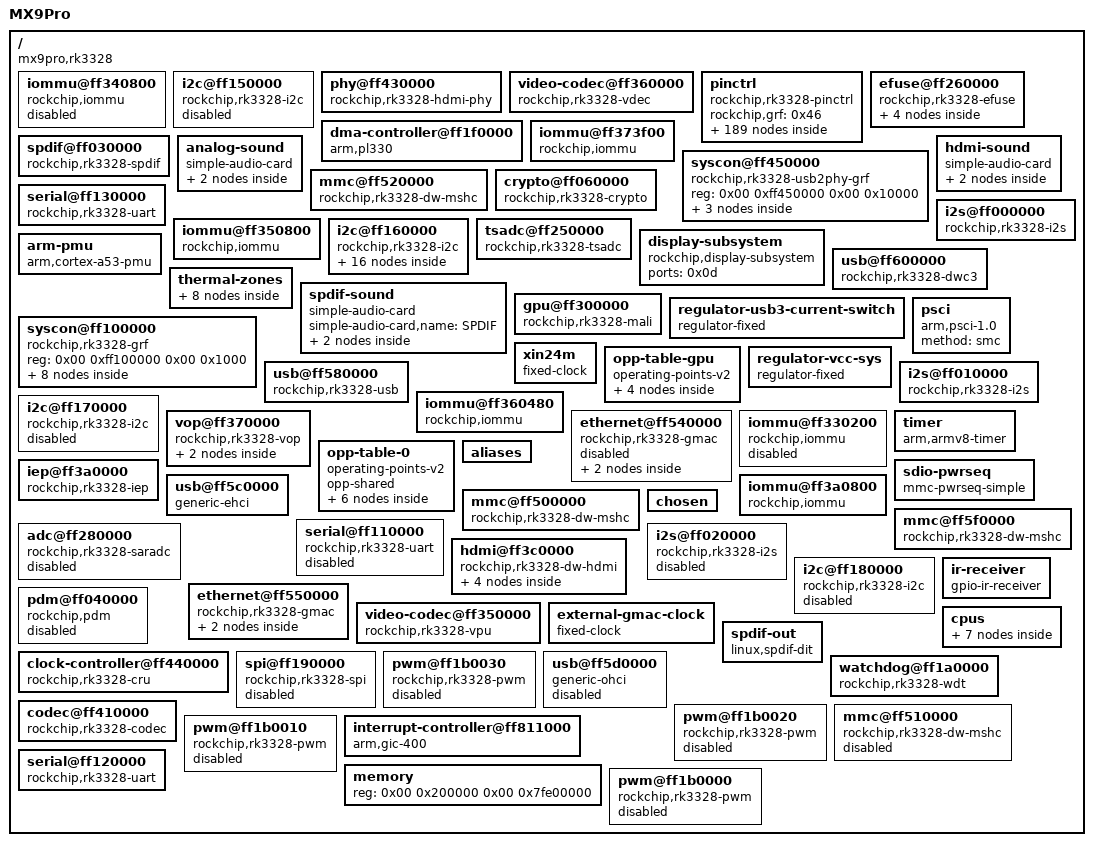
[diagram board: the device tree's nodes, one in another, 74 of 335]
/dts-v1/;

/ {
	#address-cells = <0x02>;
	model = "MX9Pro";
	serial-number = "0ee56abe064fdcdd";
	#size-cells = <0x02>;
	interrupt-parent = <0x01>;
	compatible = "mx9pro,rk3328\0rockchip,rk3328";

	iommu@ff340800 {
		clock-names = "aclk\0iface";
		interrupts = <0x00 0x62 0x04>;
		clocks = <0x02 0x8f 0x02 0x146>;
		#iommu-cells = <0x00>;
		compatible = "rockchip,iommu";
		status = "disabled";
		reg = <0x00 0xff340800 0x00 0x40>;
		phandle = <0x8f>;
	};

	i2c@ff150000 {
		pinctrl-names = "default";
		#address-cells = <0x01>;
		pinctrl-0 = <0x26>;
		clock-names = "i2c\0pclk";
		interrupts = <0x00 0x24 0x04>;
		clocks = <0x02 0x37 0x02 0xcd>;
		#size-cells = <0x00>;
		compatible = "rockchip,rk3328-i2c\0rockchip,rk3399-i2c";
		status = "disabled";
		reg = <0x00 0xff150000 0x00 0x1000>;
		phandle = <0x7a>;
	};

	phy@ff430000 {
		nvmem-cells = <0x4a>;
		clock-output-names = "hdmi_phy";
		clock-names = "sysclk\0refoclk\0refpclk";
		interrupts = <0x00 0x53 0x04>;
		clocks = <0x02 0xe4 0x49 0x02 0x79>;
		#clock-cells = <0x00>;
		#phy-cells = <0x00>;
		compatible = "rockchip,rk3328-hdmi-phy";
		status = "okay";
		nvmem-cell-names = "cpu-version";
		reg = <0x00 0xff430000 0x00 0x10000>;
		phandle = <0x42>;
	};

	video-codec@ff360000 {
		power-domains = <0x3b 0x05>;
		iommus = <0x3e>;
		clock-names = "axi\0ahb\0cabac\0core";
		assigned-clocks = <0x02 0x8b 0x02 0x41 0x02 0x42>;
		assigned-clock-rates = <0x1dcd6500 0x1dcd6500 0x11e1a300>;
		resets = <0x02 0xa6 0x02 0xa4 0x02 0xa8 0x02 0xa9 0x02 0xa5 0x02 0xa7>;
		interrupts = <0x00 0x07 0x04>;
		clocks = <0x02 0x8b 0x02 0x142 0x02 0x41 0x02 0x42>;
		compatible = "rockchip,rk3328-vdec\0rockchip,rk3399-vdec";
		reg = <0x00 0xff360000 0x00 0x480>;
		phandle = <0x91>;
		reset-names = "video_h\0video_a\0video_core\0video_cabac\0niu_a\0niu_h";
	};

	pinctrl {
		#address-cells = <0x02>;
		#size-cells = <0x02>;
		compatible = "rockchip,rk3328-pinctrl";
		ranges;
		rockchip,grf = <0x46>;
		phandle = <0xa2>;

		i2c3 {

			i2c3-xfer {
				rockchip,pins = <0x00 0x05 0x02 0x61 0x00 0x06 0x02 0x61>;
				phandle = <0x2c>;
			};

			i2c3-pins {
				rockchip,pins = <0x00 0x05 0x00 0x61 0x00 0x06 0x00 0x61>;
				phandle = <0xa8>;
			};
		};

		pcfg-pull-none-12ma {
			drive-strength = <0x0c>;
			bias-disable;
			phandle = <0x68>;
		};

		i2s1 {

			i2s1-lrcktx {
				rockchip,pins = <0x02 0x11 0x01 0x61>;
				phandle = <0xbb>;
			};

			i2s1-lrckrx {
				rockchip,pins = <0x02 0x10 0x01 0x61>;
				phandle = <0xba>;
			};

			i2s1-sleep {
				rockchip,pins = <0x02 0x0f 0x00 0x62 0x02 0x10 0x00 0x62 0x02 0x11 0x00 0x62 0x02 0x12 0x00 0x62 0x02 0x13 0x00 0x62 0x02 0x14 0x00 0x62 0x02 0x15 0x00 0x62 0x02 0x16 0x00 0x62 0x02 0x17 0x00 0x62>;
				phandle = <0xc1>;
			};

			i2s1-mclk {
				rockchip,pins = <0x02 0x0f 0x01 0x61>;
				phandle = <0xb8>;
			};

			i2s1-sdio3 {
				rockchip,pins = <0x02 0x16 0x01 0x61>;
				phandle = <0xc0>;
			};

			i2s1-sdio1 {
				rockchip,pins = <0x02 0x14 0x01 0x61>;
				phandle = <0xbe>;
			};

			i2s1-sdo {
				rockchip,pins = <0x02 0x17 0x01 0x61>;
				phandle = <0xbd>;
			};

			i2s1-sdi {
				rockchip,pins = <0x02 0x13 0x01 0x61>;
				phandle = <0xbc>;
			};

			i2s1-sdio2 {
				rockchip,pins = <0x02 0x15 0x01 0x61>;
				phandle = <0xbf>;
			};

			i2s1-sclk {
				rockchip,pins = <0x02 0x12 0x01 0x61>;
				phandle = <0xb9>;
			};
		};

		i2c1 {

			i2c1-xfer {
				rockchip,pins = <0x02 0x04 0x02 0x61 0x02 0x05 0x02 0x61>;
				phandle = <0x27>;
			};
		};

		usb3 {

			usb30-host-drv {
				rockchip,pins = <0x00 0x00 0x00 0x61>;
				phandle = <0x6f>;
			};
		};

		gpio@ff230000 {
			gpio-controller;
			interrupts = <0x00 0x35 0x04>;
			clocks = <0x02 0xca>;
			compatible = "rockchip,gpio-bank";
			#interrupt-cells = <0x02>;
			reg = <0x00 0xff230000 0x00 0x100>;
			phandle = <0x28>;
			#gpio-cells = <0x02>;
			interrupt-controller;
		};

		cif-1 {

			dvp-d2d9-m1 {
				rockchip,pins = <0x03 0x04 0x02 0x61 0x03 0x05 0x02 0x61 0x03 0x06 0x02 0x61 0x03 0x07 0x02 0x61 0x03 0x08 0x02 0x61 0x02 0x10 0x04 0x61 0x02 0x11 0x04 0x61 0x02 0x12 0x04 0x61 0x03 0x01 0x02 0x61 0x03 0x00 0x02 0x61 0x02 0x0f 0x04 0x61 0x03 0x02 0x02 0x61>;
				phandle = <0xf3>;
			};
		};

		spdif-2 {

			spdifm2-tx {
				rockchip,pins = <0x00 0x02 0x02 0x61>;
				phandle = <0x11>;
			};
		};

		pcfg-pull-down-4ma {
			drive-strength = <0x04>;
			bias-pull-down;
			phandle = <0xa6>;
		};

		wifi {

			host-wake-bt {
				rockchip,pins = <0x02 0x0f 0x00 0x6d>;
				phandle = <0x5e>;
			};

			chip-en {
				rockchip,pins = <0x02 0x13 0x00 0x6c>;
				phandle = <0x5d>;
			};

			bt-wake-host {
				rockchip,pins = <0x02 0x10 0x00 0x63>;
				phandle = <0x5c>;
			};

			wl-wake-host {
				rockchip,pins = <0x03 0x01 0x00 0x63>;
				phandle = <0x60>;
			};

			wifi_enable_h {
				rockchip,pins = <0x03 0x08 0x00 0x61>;
				phandle = <0xf8>;
			};

			wl-dis {
				rockchip,pins = <0x03 0x08 0x00 0x6c>;
				phandle = <0x5f>;
			};

			bt-dis {
				rockchip,pins = <0x02 0x15 0x00 0x6c>;
				phandle = <0x5b>;
			};
		};

		spi0-2 {

			spi0m2-tx {
				rockchip,pins = <0x03 0x01 0x04 0x63>;
				phandle = <0x2e>;
			};

			spi0m2-clk {
				rockchip,pins = <0x03 0x00 0x04 0x63>;
				phandle = <0x2d>;
			};

			spi0m2-rx {
				rockchip,pins = <0x03 0x02 0x04 0x63>;
				phandle = <0x2f>;
			};

			spi0m2-cs0 {
				rockchip,pins = <0x03 0x08 0x03 0x63>;
				phandle = <0x30>;
			};
		};

		pcfg-pull-none-2ma {
			drive-strength = <0x02>;
			bias-disable;
			phandle = <0x6a>;
		};

		sdmmc0-0 {

			sdmmc0m0-pwren {
				rockchip,pins = <0x02 0x07 0x01 0x64>;
				phandle = <0xd2>;
			};

			sdmmc0m0-pin {
				rockchip,pins = <0x02 0x07 0x00 0x64>;
				phandle = <0xd3>;
			};
		};

		spdif-0 {

			spdifm0-tx {
				rockchip,pins = <0x00 0x1b 0x01 0x61>;
				phandle = <0xd0>;
			};
		};

		tsadc_pin {

			tsadc-pin {
				rockchip,pins = <0x02 0x0d 0x00 0x61>;
				phandle = <0xf1>;
			};

			tsadc-int {
				rockchip,pins = <0x02 0x0d 0x02 0x61>;
				phandle = <0xf0>;
			};
		};

		pcfg-pull-down {
			bias-pull-down;
			phandle = <0x6b>;
		};

		gmac-1 {

			rgmiim1-pins {
				rockchip,pins = <0x01 0x0c 0x02 0x65 0x01 0x0d 0x02 0x67 0x01 0x13 0x02 0x67 0x01 0x19 0x02 0x65 0x01 0x15 0x02 0x67 0x01 0x16 0x02 0x67 0x01 0x17 0x02 0x67 0x01 0x0a 0x02 0x67 0x01 0x0b 0x02 0x67 0x01 0x08 0x02 0x65 0x01 0x09 0x02 0x65 0x01 0x0e 0x02 0x67 0x01 0x0f 0x02 0x67 0x01 0x10 0x02 0x65 0x01 0x11 0x02 0x65 0x00 0x08 0x01 0x65 0x00 0x0c 0x01 0x65 0x00 0x18 0x01 0x67 0x00 0x10 0x01 0x65 0x00 0x11 0x01 0x65 0x00 0x17 0x01 0x65 0x00 0x16 0x01 0x65>;
				phandle = <0x55>;
			};

			rmiim1-pins {
				rockchip,pins = <0x01 0x13 0x02 0x6a 0x01 0x19 0x02 0x68 0x01 0x15 0x02 0x6a 0x01 0x18 0x02 0x6a 0x01 0x16 0x02 0x6a 0x01 0x17 0x02 0x6a 0x01 0x0a 0x02 0x6a 0x01 0x0b 0x02 0x6a 0x01 0x08 0x02 0x68 0x01 0x09 0x02 0x68 0x00 0x0b 0x01 0x61 0x00 0x0c 0x01 0x61 0x00 0x18 0x01 0x61 0x00 0x13 0x01 0x61 0x00 0x10 0x01 0x61 0x00 0x11 0x01 0x61>;
				phandle = <0xec>;
			};
		};

		spi0-0 {

			spi0m0-cs0 {
				rockchip,pins = <0x02 0x0b 0x01 0x63>;
				phandle = <0xaf>;
			};

			spi0m0-cs1 {
				rockchip,pins = <0x02 0x0c 0x01 0x63>;
				phandle = <0xb2>;
			};

			spi0m0-clk {
				rockchip,pins = <0x02 0x08 0x01 0x63>;
				phandle = <0xae>;
			};

			spi0m0-tx {
				rockchip,pins = <0x02 0x09 0x01 0x63>;
				phandle = <0xb0>;
			};

			spi0m0-rx {
				rockchip,pins = <0x02 0x0a 0x01 0x63>;
				phandle = <0xb1>;
			};
		};

		i2s2-0 {

			i2s2m0-mclk {
				rockchip,pins = <0x01 0x15 0x01 0x61>;
				phandle = <0xc2>;
			};

			i2s2m0-lrcktx {
				rockchip,pins = <0x01 0x17 0x01 0x61>;
				phandle = <0xc5>;
			};

			i2s2m0-sdi {
				rockchip,pins = <0x01 0x18 0x01 0x61>;
				phandle = <0xc6>;
			};

			i2s2m0-lrckrx {
				rockchip,pins = <0x01 0x1a 0x01 0x61>;
				phandle = <0xc4>;
			};

			i2s2m0-sleep {
				rockchip,pins = <0x01 0x15 0x00 0x62 0x01 0x16 0x00 0x62 0x01 0x1a 0x00 0x62 0x01 0x17 0x00 0x62 0x01 0x18 0x00 0x62 0x01 0x19 0x00 0x62>;
				phandle = <0xc8>;
			};

			i2s2m0-sclk {
				rockchip,pins = <0x01 0x16 0x01 0x61>;
				phandle = <0xc3>;
			};

			i2s2m0-sdo {
				rockchip,pins = <0x01 0x19 0x01 0x61>;
				phandle = <0xc7>;
			};
		};

		hdmi_i2c {

			hdmii2c-xfer {
				rockchip,pins = <0x00 0x05 0x01 0x61 0x00 0x06 0x01 0x61>;
				phandle = <0x44>;
			};
		};

		gpio@ff240000 {
			gpio-controller;
			interrupts = <0x00 0x36 0x04>;
			clocks = <0x02 0xcb>;
			compatible = "rockchip,gpio-bank";
			#interrupt-cells = <0x02>;
			reg = <0x00 0xff240000 0x00 0x100>;
			phandle = <0xa4>;
			#gpio-cells = <0x02>;
			interrupt-controller;
		};

		sdmmc1 {

			sdmmc1-cmd {
				rockchip,pins = <0x01 0x0d 0x01 0x66>;
				phandle = <0xe1>;
			};

			sdmmc1-pins {
				rockchip,pins = <0x01 0x0c 0x00 0x64 0x01 0x0d 0x00 0x64 0x01 0x0e 0x00 0x64 0x01 0x0f 0x00 0x64 0x01 0x10 0x00 0x64 0x01 0x11 0x00 0x64 0x01 0x12 0x00 0x64 0x01 0x13 0x00 0x64 0x01 0x14 0x00 0x64>;
				phandle = <0xe7>;
			};

			sdmmc1-bus1 {
				rockchip,pins = <0x01 0x0e 0x01 0x66>;
				phandle = <0xe5>;
			};

			sdmmc1-clk {
				rockchip,pins = <0x01 0x0c 0x01 0x65>;
				phandle = <0xe0>;
			};

			sdmmc1-bus4 {
				rockchip,pins = <0x01 0x0e 0x01 0x66 0x01 0x0f 0x01 0x66 0x01 0x10 0x01 0x66 0x01 0x11 0x01 0x66>;
				phandle = <0xe6>;
			};

			sdmmc1-pwren {
				rockchip,pins = <0x01 0x12 0x01 0x66>;
				phandle = <0xe2>;
			};

			sdmmc1-dectn {
				rockchip,pins = <0x01 0x13 0x01 0x66>;
				phandle = <0xe4>;
			};

			sdmmc1-wrprt {
				rockchip,pins = <0x01 0x14 0x01 0x66>;
				phandle = <0xe3>;
			};
		};

		pcfg-pull-none-8ma {
			drive-strength = <0x08>;
			bias-disable;
			phandle = <0x65>;
		};

		pwm1 {

			pwm1-pin {
				rockchip,pins = <0x02 0x05 0x01 0x61>;
				phandle = <0x32>;
			};
		};

		tsadc {

			otp-pin {
				rockchip,pins = <0x02 0x0d 0x00 0x61>;
				phandle = <0x38>;
			};

			otp-out {
				rockchip,pins = <0x02 0x0d 0x01 0x61>;
				phandle = <0x39>;
			};
		};

		pwmir {

			pwmir-pin {
				rockchip,pins = <0x02 0x02 0x01 0x61>;
				phandle = <0x34>;
			};
		};

		uart2-1 {

			uart2m1-xfer {
				rockchip,pins = <0x02 0x00 0x01 0x61 0x02 0x01 0x01 0x63>;
				phandle = <0x25>;
			};
		};

		uart0 {

			uart0-rts-pin {
				rockchip,pins = <0x01 0x0a 0x00 0x61>;
				phandle = <0xab>;
			};

			uart0-cts {
				rockchip,pins = <0x01 0x0b 0x01 0x61>;
				phandle = <0x20>;
			};

			uart0-rts {
				rockchip,pins = <0x01 0x0a 0x01 0x61>;
				phandle = <0x21>;
			};

			uart0-xfer {
				rockchip,pins = <0x01 0x09 0x01 0x61 0x01 0x08 0x01 0x63>;
				phandle = <0x1f>;
			};
		};

		emmc {

			emmc-clk {
				rockchip,pins = <0x03 0x15 0x02 0x68>;
				phandle = <0x50>;
			};

			emmc-bus1 {
				rockchip,pins = <0x00 0x07 0x02 0x69>;
				phandle = <0xea>;
			};

			emmc-bus8 {
				rockchip,pins = <0x00 0x07 0x02 0x69 0x02 0x1c 0x02 0x69 0x02 0x1d 0x02 0x69 0x02 0x1e 0x02 0x69 0x02 0x1f 0x02 0x69 0x03 0x10 0x02 0x69 0x03 0x11 0x02 0x69 0x03 0x12 0x02 0x69>;
				phandle = <0x52>;
			};

			emmc-bus4 {
				rockchip,pins = <0x00 0x07 0x02 0x69 0x02 0x1c 0x02 0x69 0x02 0x1d 0x02 0x69 0x02 0x1e 0x02 0x69>;
				phandle = <0xeb>;
			};

			emmc-pwren {
				rockchip,pins = <0x03 0x16 0x02 0x61>;
				phandle = <0xe8>;
			};

			emmc-cmd {
				rockchip,pins = <0x03 0x13 0x02 0x69>;
				phandle = <0x51>;
			};

			emmc-rstnout {
				rockchip,pins = <0x03 0x14 0x02 0x61>;
				phandle = <0xe9>;
			};
		};

		pcfg-output-high {
			output-high;
			phandle = <0x6d>;
		};

		pcfg-pull-up {
			phandle = <0x63>;
			bias-pull-up;
		};

		sdmmc0ext {

			sdmmc0ext-clk {
				rockchip,pins = <0x03 0x02 0x03 0x67>;
				phandle = <0xd9>;
			};

			sdmmc0ext-bus4 {
				rockchip,pins = <0x03 0x04 0x03 0x64 0x03 0x05 0x03 0x64 0x03 0x06 0x03 0x64 0x03 0x07 0x03 0x64>;
				phandle = <0xde>;
			};

			sdmmc0ext-wrprt {
				rockchip,pins = <0x03 0x03 0x03 0x64>;
				phandle = <0xdb>;
			};

			sdmmc0ext-pins {
				rockchip,pins = <0x03 0x00 0x00 0x64 0x03 0x01 0x00 0x64 0x03 0x02 0x00 0x64 0x03 0x03 0x00 0x64 0x03 0x04 0x00 0x64 0x03 0x05 0x00 0x64 0x03 0x06 0x00 0x64 0x03 0x07 0x00 0x64>;
				phandle = <0xdf>;
			};

			sdmmc0ext-bus1 {
				rockchip,pins = <0x03 0x04 0x03 0x64>;
				phandle = <0xdd>;
			};

			sdmmc0ext-cmd {
				rockchip,pins = <0x03 0x00 0x03 0x64>;
				phandle = <0xda>;
			};

			sdmmc0ext-dectn {
				rockchip,pins = <0x03 0x01 0x03 0x64>;
				phandle = <0xdc>;
			};
		};

		pcfg-input {
			phandle = <0xa7>;
			input-enable;
		};

		pcfg-pull-up-2ma {
			drive-strength = <0x02>;
			phandle = <0xa5>;
			bias-pull-up;
		};

		i2c2 {

			i2c2-xfer {
				rockchip,pins = <0x02 0x0d 0x01 0x61 0x02 0x0e 0x01 0x61>;
				phandle = <0x2b>;
			};
		};

		pmic {

			pmic-int-l {
				rockchip,pins = <0x02 0x06 0x00 0x63>;
				phandle = <0x29>;
			};
		};

		pcfg-pull-none {
			bias-disable;
			phandle = <0x61>;
		};

		pcfg-pull-none-4ma {
			drive-strength = <0x04>;
			bias-disable;
			phandle = <0x67>;
		};

		gpio@ff210000 {
			gpio-controller;
			interrupts = <0x00 0x33 0x04>;
			clocks = <0x02 0xc8>;
			compatible = "rockchip,gpio-bank";
			#interrupt-cells = <0x02>;
			reg = <0x00 0xff210000 0x00 0x100>;
			phandle = <0x6e>;
			#gpio-cells = <0x02>;
			interrupt-controller;
		};

		pdm-0 {

			pdmm0-sdi3 {
				rockchip,pins = <0x02 0x16 0x02 0x61>;
				phandle = <0x16>;
			};

			pdmm0-sdi1 {
				rockchip,pins = <0x02 0x14 0x02 0x61>;
				phandle = <0x14>;
			};

			pdmm0-sdi2-sleep {
				rockchip,pins = <0x02 0x15 0x00 0x62>;
				phandle = <0x1a>;
			};

			pdmm0-fsync {
				rockchip,pins = <0x02 0x17 0x02 0x61>;
				phandle = <0xa9>;
			};

			pdmm0-sdi3-sleep {
				rockchip,pins = <0x02 0x16 0x00 0x62>;
				phandle = <0x1b>;
			};

			pdmm0-sdi2 {
				rockchip,pins = <0x02 0x15 0x02 0x61>;
				phandle = <0x15>;
			};

			pdmm0-sdi0 {
				rockchip,pins = <0x02 0x13 0x02 0x61>;
				phandle = <0x13>;
			};

			pdmm0-sdi0-sleep {
				rockchip,pins = <0x02 0x13 0x00 0x62>;
				phandle = <0x18>;
			};

			pdmm0-clk-sleep {
				rockchip,pins = <0x02 0x12 0x00 0x62>;
				phandle = <0x17>;
			};

			pdmm0-clk {
				rockchip,pins = <0x02 0x12 0x02 0x61>;
				phandle = <0x12>;
			};

			pdmm0-fsync-sleep {
				rockchip,pins = <0x02 0x17 0x00 0x62>;
				phandle = <0xaa>;
			};

			pdmm0-sdi1-sleep {
				rockchip,pins = <0x02 0x14 0x00 0x62>;
				phandle = <0x19>;
			};
		};

		i2c0 {

			i2c0-xfer {
				rockchip,pins = <0x02 0x18 0x01 0x61 0x02 0x19 0x01 0x61>;
				phandle = <0x26>;
			};
		};

		sdmmc0-1 {

			sdmmc0m1-pwren {
				rockchip,pins = <0x00 0x1e 0x03 0x64>;
				phandle = <0xd4>;
			};

			sdmmc0m1-pin {
				rockchip,pins = <0x00 0x1e 0x00 0x64>;
				phandle = <0xd5>;
			};
		};

		cif-0 {

			dvp-d2d9-m0 {
				rockchip,pins = <0x03 0x04 0x02 0x61 0x03 0x05 0x02 0x61 0x03 0x06 0x02 0x61 0x03 0x07 0x02 0x61 0x03 0x08 0x02 0x61 0x03 0x09 0x02 0x61 0x03 0x0a 0x02 0x61 0x03 0x0b 0x02 0x61 0x03 0x01 0x02 0x61 0x03 0x00 0x02 0x61 0x03 0x03 0x02 0x61 0x03 0x02 0x02 0x61>;
				phandle = <0xf2>;
			};
		};

		spdif-1 {

			spdifm1-tx {
				rockchip,pins = <0x02 0x11 0x02 0x61>;
				phandle = <0xd1>;
			};
		};

		pcfg-input-high {
			phandle = <0x62>;
			bias-pull-up;
			input-enable;
		};

		pcfg-pull-up-8ma {
			drive-strength = <0x08>;
			phandle = <0x66>;
			bias-pull-up;
		};

		spi0-1 {

			spi0m1-cs0 {
				rockchip,pins = <0x03 0x1a 0x02 0x63>;
				phandle = <0xb4>;
			};

			spi0m1-tx {
				rockchip,pins = <0x03 0x19 0x02 0x63>;
				phandle = <0xb5>;
			};

			spi0m1-rx {
				rockchip,pins = <0x03 0x18 0x02 0x63>;
				phandle = <0xb6>;
			};

			spi0m1-cs1 {
				rockchip,pins = <0x03 0x1b 0x02 0x63>;
				phandle = <0xb7>;
			};

			spi0m1-clk {
				rockchip,pins = <0x03 0x17 0x02 0x63>;
				phandle = <0xb3>;
			};
		};

		i2s2-1 {

			i2s2m1-mclk {
				rockchip,pins = <0x01 0x15 0x01 0x61>;
				phandle = <0xc9>;
			};

			i2s2m1-sdo {
				rockchip,pins = <0x03 0x01 0x06 0x61>;
				phandle = <0xce>;
			};

			i2s2m1-lrcktx {
				rockchip,pins = <0x03 0x08 0x04 0x61>;
				phandle = <0xcc>;
			};

			i2s2m1-sdi {
				rockchip,pins = <0x03 0x02 0x06 0x61>;
				phandle = <0xcd>;
			};

			i2sm1-lrckrx {
				rockchip,pins = <0x03 0x08 0x06 0x61>;
				phandle = <0xcb>;
			};

			i2s2m1-sleep {
				rockchip,pins = <0x01 0x15 0x00 0x62 0x03 0x00 0x00 0x62 0x03 0x08 0x00 0x62 0x03 0x02 0x00 0x62 0x03 0x01 0x00 0x62>;
				phandle = <0xcf>;
			};

			i2s2m1-sclk {
				rockchip,pins = <0x03 0x00 0x06 0x61>;
				phandle = <0xca>;
			};
		};

		pcfg-pull-up-12ma {
			drive-strength = <0x0c>;
			phandle = <0x69>;
			bias-pull-up;
		};

		hdmi_pin {

			hdmi-cec {
				rockchip,pins = <0x00 0x03 0x01 0x61>;
				phandle = <0x43>;
			};

			hdmi-hpd {
				rockchip,pins = <0x00 0x04 0x01 0x6b>;
				phandle = <0x45>;
			};
		};

		pcfg-output-low {
			phandle = <0x6c>;
			output-low;
		};

		gmac2phy {

			fephyled-speed10 {
				rockchip,pins = <0x00 0x1e 0x01 0x61>;
				phandle = <0xed>;
			};

			fephyled-linkm1 {
				rockchip,pins = <0x02 0x18 0x02 0x61>;
				phandle = <0x58>;
			};

			fephyled-duplex {
				rockchip,pins = <0x00 0x1e 0x02 0x61>;
				phandle = <0xee>;
			};

			fephyled-rxm1 {
				rockchip,pins = <0x02 0x19 0x02 0x61>;
				phandle = <0x57>;
			};

			fephyled-txm1 {
				rockchip,pins = <0x02 0x19 0x03 0x61>;
				phandle = <0xef>;
			};
		};

		pwm2 {

			pwm2-pin {
				rockchip,pins = <0x02 0x06 0x01 0x61>;
				phandle = <0x33>;
			};
		};

		gpio@ff220000 {
			gpio-controller;
			interrupts = <0x00 0x34 0x04>;
			clocks = <0x02 0xc9>;
			compatible = "rockchip,gpio-bank";
			#interrupt-cells = <0x02>;
			reg = <0x00 0xff220000 0x00 0x100>;
			phandle = <0xa3>;
			#gpio-cells = <0x02>;
			interrupt-controller;
		};

		uart1 {

			uart1-cts {
				rockchip,pins = <0x03 0x07 0x04 0x61>;
				phandle = <0x23>;
			};

			uart1-rts-pin {
				rockchip,pins = <0x03 0x05 0x00 0x61>;
				phandle = <0xac>;
			};

			uart1-rts {
				rockchip,pins = <0x03 0x05 0x04 0x61>;
				phandle = <0x24>;
			};

			uart1-xfer {
				rockchip,pins = <0x03 0x04 0x04 0x61 0x03 0x06 0x04 0x63>;
				phandle = <0x22>;
			};
		};

		sdmmc0 {

			sdmmc0-pins {
				rockchip,pins = <0x01 0x06 0x00 0x64 0x01 0x04 0x00 0x64 0x01 0x05 0x00 0x64 0x01 0x07 0x00 0x64 0x01 0x03 0x00 0x64 0x01 0x02 0x00 0x64 0x01 0x01 0x00 0x64 0x01 0x00 0x00 0x64>;
				phandle = <0xd8>;
			};

			sdmmc0-bus1 {
				rockchip,pins = <0x01 0x00 0x01 0x66>;
				phandle = <0xd7>;
			};

			sdmmc0-dectn {
				rockchip,pins = <0x01 0x05 0x01 0x64>;
				phandle = <0x4e>;
			};

			sdmmc0-bus4 {
				rockchip,pins = <0x01 0x00 0x01 0x66 0x01 0x01 0x01 0x66 0x01 0x02 0x01 0x66 0x01 0x03 0x01 0x66>;
				phandle = <0x4f>;
			};

			sdmmc0-wrprt {
				rockchip,pins = <0x01 0x07 0x01 0x64>;
				phandle = <0xd6>;
			};

			sdmmc0-cmd {
				rockchip,pins = <0x01 0x04 0x01 0x66>;
				phandle = <0x4d>;
			};

			sdmmc0-clk {
				rockchip,pins = <0x01 0x06 0x01 0x65>;
				phandle = <0x4c>;
			};
		};

		pcfg-pull-up-4ma {
			drive-strength = <0x04>;
			phandle = <0x64>;
			bias-pull-up;
		};

		pwm0 {

			pwm0-pin {
				rockchip,pins = <0x02 0x04 0x01 0x61>;
				phandle = <0x31>;
			};
		};

		uart2-0 {

			uart2m0-xfer {
				rockchip,pins = <0x01 0x00 0x02 0x61 0x01 0x01 0x02 0x63>;
				phandle = <0xad>;
			};
		};
	};

	efuse@ff260000 {
		#address-cells = <0x01>;
		clock-names = "pclk_efuse";
		clocks = <0x02 0x3e>;
		#size-cells = <0x01>;
		compatible = "rockchip,rk3328-efuse";
		rockchip,efuse-size = <0x20>;
		reg = <0x00 0xff260000 0x00 0x50>;
		phandle = <0x89>;

		id@7 {
			reg = <0x07 0x10>;
			phandle = <0x8a>;
		};

		cpu-version@1a {
			bits = <0x03 0x03>;
			reg = <0x1a 0x01>;
			phandle = <0x4a>;
		};

		logic-leakage@19 {
			reg = <0x19 0x01>;
			phandle = <0x8c>;
		};

		cpu-leakage@17 {
			reg = <0x17 0x01>;
			phandle = <0x8b>;
		};
	};

	dma-controller@ff1f0000 {
		clock-names = "apb_pclk";
		interrupts = <0x00 0x00 0x04 0x00 0x01 0x04>;
		clocks = <0x02 0x86>;
		arm,pl330-periph-burst;
		compatible = "arm,pl330\0arm,primecell";
		reg = <0x00 0xff1f0000 0x00 0x4000>;
		phandle = <0x10>;
		#dma-cells = <0x01>;
	};

	iommu@ff373f00 {
		clock-names = "aclk\0iface";
		interrupts = <0x00 0x20 0x04>;
		clocks = <0x02 0x91 0x02 0x13b>;
		#iommu-cells = <0x00>;
		compatible = "rockchip,iommu";
		status = "okay";
		reg = <0x00 0xff373f00 0x00 0x100>;
		phandle = <0x3f>;
	};

	spdif@ff030000 {
		pinctrl-names = "default";
		pinctrl-0 = <0xd1>;
		clock-names = "mclk\0hclk";
		interrupts = <0x00 0x1d 0x04>;
		clocks = <0x02 0x2e 0x02 0x13a>;
		dma-names = "tx";
		#sound-dai-cells = <0x00>;
		compatible = "rockchip,rk3328-spdif";
		status = "okay";
		reg = <0x00 0xff030000 0x00 0x1000>;
		phandle = <0x74>;
		dmas = <0x10 0x0a>;
	};

	analog-sound {
		simple-audio-card,name = "Analog A/V";
		simple-audio-card,format = "i2s";
		compatible = "simple-audio-card";
		status = "okay";
		phandle = <0x70>;
		simple-audio-card,mclk-fs = <0x100>;

		simple-audio-card,cpu {
			sound-dai = <0x07>;
		};

		simple-audio-card,codec {
			sound-dai = <0x08>;
		};
	};

	syscon@ff450000 {
		#address-cells = <0x01>;
		#size-cells = <0x01>;
		compatible = "rockchip,rk3328-usb2phy-grf\0syscon\0simple-mfd";
		reg = <0x00 0xff450000 0x00 0x10000>;
		phandle = <0x96>;

		usb2phy@100 {
			clock-output-names = "usb480m_phy";
			clock-names = "phyclk";
			assigned-clocks = <0x02 0x7b>;
			assigned-clock-parents = <0x4b>;
			clocks = <0x49>;
			#clock-cells = <0x00>;
			compatible = "rockchip,rk3328-usb2phy";
			status = "okay";
			reg = <0x100 0x10>;
			phandle = <0x4b>;

			host-port {
				interrupts = <0x00 0x3e 0x04>;
				#phy-cells = <0x00>;
				status = "okay";
				interrupt-names = "linestate";
				phandle = <0x5a>;
			};

			otg-port {
				interrupts = <0x00 0x3b 0x04 0x00 0x3c 0x04 0x00 0x3d 0x04>;
				#phy-cells = <0x00>;
				status = "okay";
				interrupt-names = "otg-bvalid\0otg-id\0linestate";
				phandle = <0x59>;
			};
		};
	};

	mmc@ff520000 {
		fifo-depth = <0x100>;
		pinctrl-names = "default";
		pinctrl-0 = <0x50 0x51 0x52>;
		clock-names = "biu\0ciu\0ciu-drive\0ciu-sample";
		vqmmc-supply = <0x1d>;
		mmc-hs200-1_8v;
		bus-width = <0x08>;
		non-removable;
		no-sdio;
		resets = <0x02 0x6f>;
		interrupts = <0x00 0x0e 0x04>;
		clocks = <0x02 0x13f 0x02 0x23 0x02 0x4c 0x02 0x50>;
		vmmc-supply = <0x1c>;
		no-sd;
		mmc-ddr-1_8v;
		compatible = "rockchip,rk3328-dw-mshc\0rockchip,rk3288-dw-mshc";
		status = "okay";
		reg = <0x00 0xff520000 0x00 0x4000>;
		phandle = <0x99>;
		max-frequency = <0x8f0d180>;
		cap-mmc-highspeed;
		reset-names = "reset";
	};

	crypto@ff060000 {
		clock-names = "hclk_master\0hclk_slave\0sclk";
		resets = <0x02 0x44>;
		interrupts = <0x00 0x1e 0x04>;
		clocks = <0x02 0x150 0x02 0x151 0x02 0x3b>;
		compatible = "rockchip,rk3328-crypto";
		reg = <0x00 0xff060000 0x00 0x4000>;
		phandle = <0xa1>;
		reset-names = "crypto-rst";
	};

	serial@ff130000 {
		reg-io-width = <0x04>;
		pinctrl-names = "default";
		pinctrl-0 = <0x25>;
		clock-names = "baudclk\0apb_pclk";
		interrupts = <0x00 0x39 0x04>;
		clocks = <0x02 0x28 0x02 0xd4>;
		dma-names = "tx\0rx";
		compatible = "rockchip,rk3328-uart\0snps,dw-apb-uart";
		status = "okay";
		reg = <0x00 0xff130000 0x00 0x100>;
		phandle = <0x79>;
		dmas = <0x10 0x06 0x10 0x07>;
		reg-shift = <0x02>;
	};

	hdmi-sound {
		simple-audio-card,name = "HDMI";
		simple-audio-card,format = "i2s";
		compatible = "simple-audio-card";
		status = "okay";
		phandle = <0x72>;
		simple-audio-card,mclk-fs = <0x80>;

		simple-audio-card,cpu {
			sound-dai = <0x0e>;
		};

		simple-audio-card,codec {
			sound-dai = <0x0f>;
		};
	};

	i2s@ff000000 {
		clock-names = "i2s_clk\0i2s_hclk";
		interrupts = <0x00 0x1a 0x04>;
		clocks = <0x02 0x29 0x02 0x137>;
		dma-names = "tx\0rx";
		#sound-dai-cells = <0x00>;
		compatible = "rockchip,rk3328-i2s\0rockchip,rk3066-i2s";
		status = "okay";
		reg = <0x00 0xff000000 0x00 0x1000>;
		phandle = <0x0e>;
		dmas = <0x10 0x0b 0x10 0x0c>;
	};

	iommu@ff350800 {
		power-domains = <0x3b 0x08>;
		clock-names = "aclk\0iface";
		interrupts = <0x00 0x0b 0x04>;
		clocks = <0x02 0x8f 0x02 0x146>;
		#iommu-cells = <0x00>;
		compatible = "rockchip,iommu";
		reg = <0x00 0xff350800 0x00 0x40>;
		phandle = <0x3d>;
	};

	i2c@ff160000 {
		pinctrl-names = "default";
		#address-cells = <0x01>;
		pinctrl-0 = <0x27>;
		clock-names = "i2c\0pclk";
		i2c-scl-rising-time-ns = <0x53>;
		i2c-scl-falling-time-ns = <0x05>;
		interrupts = <0x00 0x25 0x04>;
		clocks = <0x02 0x38 0x02 0xce>;
		#size-cells = <0x00>;
		clock-frequency = <0xf4240>;
		compatible = "rockchip,rk3328-i2c\0rockchip,rk3399-i2c";
		status = "okay";
		reg = <0x00 0xff160000 0x00 0x1000>;
		phandle = <0x7b>;

		pmic@18 {
			system-power-controller;
			pinctrl-names = "default";
			pinctrl-0 = <0x29>;
			wakeup-source;
			interrupts = <0x06 0x08>;
			#clock-cells = <0x00>;
			interrupt-parent = <0x28>;
			vcc1-supply = <0x2a>;
			vcc2-supply = <0x2a>;
			compatible = "rockchip,rk805";
			vcc3-supply = <0x2a>;
			vcc4-supply = <0x2a>;
			vcc5-supply = <0x1c>;
			reg = <0x18>;
			vcc6-supply = <0x1c>;

			regulators {

				DCDC_REG4 {
					regulator-max-microvolt = <0x325aa0>;
					regulator-boot-on;
					regulator-always-on;
					regulator-min-microvolt = <0x325aa0>;
					regulator-name = "vcc_io";
					phandle = <0x1c>;

					regulator-state-mem {
						regulator-suspend-microvolt = <0x325aa0>;
						regulator-on-in-suspend;
					};
				};

				DCDC_REG2 {
					regulator-max-microvolt = <0x149970>;
					regulator-boot-on;
					regulator-always-on;
					regulator-min-microvolt = <0xaae60>;
					regulator-name = "vdd_arm";
					phandle = <0x06>;

					regulator-state-mem {
						regulator-suspend-microvolt = <0xe7ef0>;
						regulator-on-in-suspend;
					};
				};

				LDO_REG2 {
					regulator-max-microvolt = <0x1b7740>;
					regulator-boot-on;
					regulator-always-on;
					regulator-min-microvolt = <0x1b7740>;
					regulator-name = "vcc_18emmc";
					phandle = <0x1d>;

					regulator-state-mem {
						regulator-suspend-microvolt = <0x1b7740>;
						regulator-on-in-suspend;
					};
				};

				DCDC_REG3 {
					regulator-boot-on;
					regulator-always-on;
					regulator-name = "vcc_ddr";
					phandle = <0x7c>;

					regulator-state-mem {
						regulator-on-in-suspend;
					};
				};

				LDO_REG3 {
					regulator-max-microvolt = <0x10c8e0>;
					regulator-boot-on;
					regulator-always-on;
					regulator-min-microvolt = <0x10c8e0>;
					regulator-name = "vdd_11";
					phandle = <0x7d>;

					regulator-state-mem {
						regulator-suspend-microvolt = <0x10c8e0>;
						regulator-on-in-suspend;
					};
				};

				DCDC_REG1 {
					regulator-max-microvolt = <0x149970>;
					regulator-boot-on;
					regulator-always-on;
					regulator-min-microvolt = <0xaae60>;
					regulator-name = "vdd_logic";
					phandle = <0x3c>;

					regulator-state-mem {
						regulator-suspend-microvolt = <0xf4240>;
						regulator-on-in-suspend;
					};
				};

				LDO_REG1 {
					regulator-max-microvolt = <0x1b7740>;
					regulator-boot-on;
					regulator-always-on;
					regulator-min-microvolt = <0x1b7740>;
					regulator-name = "vdd_18";
					phandle = <0x1e>;

					regulator-state-mem {
						regulator-suspend-microvolt = <0x1b7740>;
						regulator-on-in-suspend;
					};
				};
			};
		};
	};

	tsadc@ff250000 {
		pinctrl-names = "init\0default\0sleep";
		pinctrl-2 = <0x38>;
		pinctrl-0 = <0x38>;
		clock-names = "tsadc\0apb_pclk";
		rockchip,hw-tshut-polarity = <0x00>;
		assigned-clocks = <0x02 0x24>;
		assigned-clock-rates = <0xc350>;
		resets = <0x02 0x42>;
		interrupts = <0x00 0x3a 0x04>;
		rockchip,hw-tshut-mode = <0x00>;
		clocks = <0x02 0x24 0x02 0xd5>;
		#thermal-sensor-cells = <0x01>;
		compatible = "rockchip,rk3328-tsadc";
		pinctrl-1 = <0x39>;
		status = "okay";
		reg = <0x00 0xff250000 0x00 0x100>;
		phandle = <0x35>;
		reset-names = "tsadc-apb";
		rockchip,hw-tshut-temp = <0x186a0>;
	};

	display-subsystem {
		ports = <0x0d>;
		compatible = "rockchip,display-subsystem";
		phandle = <0x71>;
	};

	usb@ff600000 {
		snps,dis_enblslpm_quirk;
		clock-names = "ref_clk\0suspend_clk\0bus_clk";
		snps,dis-u2-freeclk-exists-quirk;
		phy_type = "utmi_wide";
		snps,dis_u2_susphy_quirk;
		interrupts = <0x00 0x43 0x04>;
		clocks = <0x02 0x60 0x02 0x61 0x02 0x84>;
		compatible = "rockchip,rk3328-dwc3\0snps,dwc3";
		snps,dis_u3_susphy_quirk;
		snps,dis-del-phy-power-chg-quirk;
		status = "okay";
		reg = <0x00 0xff600000 0x00 0x100000>;
		phandle = <0xa0>;
		dr_mode = "host";
		snps,dis-tx-ipgap-linecheck-quirk;
	};

	arm-pmu {
		interrupt-affinity = <0x09 0x0a 0x0b 0x0c>;
		interrupts = <0x00 0x64 0x04 0x00 0x65 0x04 0x00 0x66 0x04 0x00 0x67 0x04>;
		compatible = "arm,cortex-a53-pmu";
	};

	thermal-zones {

		soc-thermal {
			polling-delay = <0x3e8>;
			polling-delay-passive = <0x14>;
			thermal-sensors = <0x35 0x00>;
			sustainable-power = <0x3e8>;
			phandle = <0x86>;

			trips {

				trip-point0 {
					temperature = <0x11170>;
					hysteresis = <0x7d0>;
					type = "passive";
					phandle = <0x87>;
				};

				soc-crit {
					temperature = <0x17318>;
					hysteresis = <0x7d0>;
					type = "critical";
					phandle = <0x88>;
				};

				trip-point1 {
					temperature = <0x14c08>;
					hysteresis = <0x7d0>;
					type = "passive";
					phandle = <0x36>;
				};
			};

			cooling-maps {

				map0 {
					trip = <0x36>;
					cooling-device = <0x09 0xffffffff 0xffffffff 0x0a 0xffffffff 0xffffffff 0x0b 0xffffffff 0xffffffff 0x0c 0xffffffff 0xffffffff>;
					contribution = <0x1000>;
				};

				map1 {
					trip = <0x36>;
					cooling-device = <0x37 0xffffffff 0xffffffff>;
					contribution = <0x1000>;
				};
			};
		};
	};

	spdif-sound {
		simple-audio-card,name = "SPDIF";
		compatible = "simple-audio-card";
		status = "okay";
		phandle = <0xf7>;

		simple-audio-card,cpu {
			sound-dai = <0x74>;
		};

		simple-audio-card,codec {
			sound-dai = <0xf6>;
		};
	};

	gpu@ff300000 {
		power-domains = <0x3b 0x01>;
		mali-supply = <0x3c>;
		clock-names = "bus\0core";
		resets = <0x02 0x66>;
		interrupts = <0x00 0x5a 0x04 0x00 0x57 0x04 0x00 0x5d 0x04 0x00 0x58 0x04 0x00 0x59 0x04 0x00 0x5b 0x04 0x00 0x5c 0x04>;
		clocks = <0x02 0x87 0x02 0x87>;
		compatible = "rockchip,rk3328-mali\0arm,mali-450";
		interrupt-names = "gp\0gpmmu\0pp\0pp0\0ppmmu0\0pp1\0ppmmu1";
		reg = <0x00 0xff300000 0x00 0x30000>;
		phandle = <0x37>;
		operating-points-v2 = <0x3a>;
		#cooling-cells = <0x02>;
	};

	regulator-usb3-current-switch {
		pinctrl-names = "default";
		gpio = <0x6e 0x00 0x00>;
		pinctrl-0 = <0x6f>;
		enable-active-high;
		regulator-name = "vcc_host_5v";
		compatible = "regulator-fixed";
		phandle = <0xf4>;
		vin-supply = <0x2a>;
	};

	syscon@ff100000 {
		compatible = "rockchip,rk3328-grf\0syscon\0simple-mfd";
		reg = <0x00 0xff100000 0x00 0x1000>;
		phandle = <0x46>;

		gpio {
			gpio-controller;
			compatible = "rockchip,rk3328-grf-gpio";
			phandle = <0x48>;
			#gpio-cells = <0x02>;
		};

		reboot-mode {
			mode-normal = <0x5242c300>;
			mode-loader = <0x5242c301>;
			mode-bootloader = <0x5242c309>;
			mode-recovery = <0x5242c303>;
			offset = <0x5c8>;
			compatible = "syscon-reboot-mode";
		};

		io-domains {
			vccio1-supply = <0x1c>;
			vccio2-supply = <0x1d>;
			vccio3-supply = <0x1c>;
			vccio4-supply = <0x1e>;
			pmuio-supply = <0x1c>;
			vccio5-supply = <0x1c>;
			vccio6-supply = <0x1e>;
			compatible = "rockchip,rk3328-io-voltage-domain";
			status = "okay";
			phandle = <0x76>;
		};

		power-controller {
			#address-cells = <0x01>;
			#size-cells = <0x00>;
			#power-domain-cells = <0x01>;
			compatible = "rockchip,rk3328-power-controller";
			phandle = <0x3b>;

			power-domain@5 {
				clocks = <0x02 0x8b 0x02 0x142 0x02 0x41 0x02 0x42>;
				#power-domain-cells = <0x00>;
				reg = <0x05>;
			};

			power-domain@1 {
				clocks = <0x02 0x87>;
				#power-domain-cells = <0x00>;
				reg = <0x01>;
			};

			power-domain@8 {
				clocks = <0x02 0x8f 0x02 0x146>;
				#power-domain-cells = <0x00>;
				reg = <0x08>;
			};

			power-domain@6 {
				clocks = <0x02 0x44>;
				#power-domain-cells = <0x00>;
				reg = <0x06>;
			};
		};
	};

	psci {
		method = "smc";
		compatible = "arm,psci-1.0\0arm,psci-0.2";
	};

	xin24m {
		clock-output-names = "xin24m";
		#clock-cells = <0x00>;
		clock-frequency = <0x16e3600>;
		compatible = "fixed-clock";
		phandle = <0x49>;
	};

	opp-table-gpu {
		compatible = "operating-points-v2";
		phandle = <0x3a>;

		opp-300000000 {
			opp-microvolt = <0x106738>;
			opp-hz = <0x00 0x11e1a300>;
		};

		opp-500000000 {
			opp-microvolt = <0x118c30>;
			opp-hz = <0x00 0x1dcd6500>;
			status = "disabled";
		};

		opp-200000000 {
			opp-microvolt = <0x106738>;
			opp-hz = <0x00 0xbebc200>;
		};

		opp-400000000 {
			opp-microvolt = <0x106738>;
			opp-hz = <0x00 0x17d78400>;
		};
	};

	regulator-vcc-sys {
		regulator-max-microvolt = <0x4c4b40>;
		regulator-min-microvolt = <0x4c4b40>;
		regulator-name = "vcc_sys";
		compatible = "regulator-fixed";
		phandle = <0x2a>;
	};

	usb@ff580000 {
		g-np-tx-fifo-size = <0x10>;
		phy-names = "usb2-phy";
		clock-names = "otg";
		g-tx-fifo-size = <0x100 0x80 0x80 0x40 0x20 0x10>;
		interrupts = <0x00 0x17 0x04>;
		clocks = <0x02 0x14d>;
		g-rx-fifo-size = <0x118>;
		compatible = "rockchip,rk3328-usb\0rockchip,rk3066-usb\0snps,dwc2";
		status = "okay";
		phys = <0x59>;
		reg = <0x00 0xff580000 0x00 0x40000>;
		phandle = <0x9c>;
		dr_mode = "host";
	};

	i2s@ff010000 {
		clock-names = "i2s_clk\0i2s_hclk";
		interrupts = <0x00 0x1b 0x04>;
		clocks = <0x02 0x2a 0x02 0x138>;
		dma-names = "tx\0rx";
		#sound-dai-cells = <0x00>;
		compatible = "rockchip,rk3328-i2s\0rockchip,rk3066-i2s";
		status = "okay";
		reg = <0x00 0xff010000 0x00 0x1000>;
		phandle = <0x07>;
		dmas = <0x10 0x0e 0x10 0x0f>;
	};

	iommu@ff360480 {
		power-domains = <0x3b 0x05>;
		clock-names = "aclk\0iface";
		interrupts = <0x00 0x4a 0x04>;
		clocks = <0x02 0x8b 0x02 0x142>;
		#iommu-cells = <0x00>;
		compatible = "rockchip,iommu";
		reg = <0x00 0xff360480 0x00 0x40 0x00 0xff3604c0 0x00 0x40>;
		phandle = <0x3e>;
	};

	i2c@ff170000 {
		pinctrl-names = "default";
		#address-cells = <0x01>;
		pinctrl-0 = <0x2b>;
		clock-names = "i2c\0pclk";
		interrupts = <0x00 0x26 0x04>;
		clocks = <0x02 0x39 0x02 0xcf>;
		#size-cells = <0x00>;
		compatible = "rockchip,rk3328-i2c\0rockchip,rk3399-i2c";
		status = "disabled";
		reg = <0x00 0xff170000 0x00 0x1000>;
		phandle = <0x7e>;
	};

	vop@ff370000 {
		iommus = <0x3f>;
		clock-names = "aclk_vop\0dclk_vop\0hclk_vop";
		resets = <0x02 0x85 0x02 0x86 0x02 0x87>;
		interrupts = <0x00 0x20 0x04>;
		clocks = <0x02 0x91 0x02 0x78 0x02 0x13b>;
		compatible = "rockchip,rk3328-vop";
		status = "okay";
		reg = <0x00 0xff370000 0x00 0x3efc>;
		phandle = <0x92>;
		reset-names = "axi\0ahb\0dclk";

		port {
			phandle = <0x0d>;

			endpoint {
				remote-endpoint = <0x40>;
				phandle = <0x47>;
			};
		};
	};

	ethernet@ff540000 {
		pinctrl-names = "default";
		phy-supply = <0x1c>;
		phy-mode = "rgmii";
		snps,txpbl = <0x04>;
		pinctrl-0 = <0x55>;
		clock-names = "stmmaceth\0mac_clk_rx\0mac_clk_tx\0clk_mac_ref\0clk_mac_refout\0aclk_mac\0pclk_mac";
		assigned-clocks = <0x02 0x64 0x02 0x66>;
		assigned-clock-parents = <0x53 0x53>;
		resets = <0x02 0x63>;
		interrupts = <0x00 0x18 0x04>;
		clocks = <0x02 0x64 0x02 0x57 0x02 0x58 0x02 0x5a 0x02 0x59 0x02 0x96 0x02 0xdf>;
		snps,pbl = <0x04>;
		clock_in_out = "input";
		compatible = "rockchip,rk3328-gmac";
		status = "disabled";
		rockchip,grf = <0x46>;
		tx-fifo-depth = <0x800>;
		interrupt-names = "macirq";
		rx-fifo-depth = <0x1000>;
		reg = <0x00 0xff540000 0x00 0x10000>;
		rx_delay = <0x11>;
		phandle = <0x9a>;
		phy-handle = <0x54>;
		reset-names = "stmmaceth";
		tx_delay = <0x26>;

		mdio {
			#address-cells = <0x01>;
			#size-cells = <0x00>;
			compatible = "snps,dwmac-mdio";

			ethernet-phy@0 {
				reg = <0x00>;
				phandle = <0x54>;
			};
		};
	};

	iommu@ff330200 {
		clock-names = "aclk\0iface";
		interrupts = <0x00 0x60 0x04>;
		clocks = <0x02 0x93 0x02 0xdd>;
		#iommu-cells = <0x00>;
		compatible = "rockchip,iommu";
		status = "disabled";
		reg = <0x00 0xff330200 0x00 0x100>;
		phandle = <0x8e>;
	};

	timer {
		interrupts = <0x01 0x0d 0xf08 0x01 0x0e 0xf08 0x01 0x0b 0xf08 0x01 0x0a 0xf08>;
		compatible = "arm,armv8-timer";
	};

	opp-table-0 {
		opp-shared;
		compatible = "operating-points-v2";
		phandle = <0x04>;

		opp-1200000000 {
			opp-microvolt = <0x12b128>;
			opp-hz = <0x00 0x47868c00>;
			clock-latency-ns = <0x9c40>;
		};

		opp-1008000000 {
			opp-microvolt = <0x10c8e0>;
			opp-hz = <0x00 0x3c14dc00>;
			clock-latency-ns = <0x9c40>;
		};

		opp-1296000000 {
			opp-microvolt = <0x13d620>;
			opp-hz = <0x00 0x4d3f6400>;
			clock-latency-ns = <0x9c40>;
		};

		opp-816000000 {
			opp-microvolt = <0xf4240>;
			opp-hz = <0x00 0x30a32c00>;
			clock-latency-ns = <0x9c40>;
		};

		opp-600000000 {
			opp-microvolt = <0xe7ef0>;
			opp-hz = <0x00 0x23c34600>;
			clock-latency-ns = <0x9c40>;
		};

		opp-408000000 {
			opp-microvolt = <0xe7ef0>;
			opp-hz = <0x00 0x18519600>;
			opp-suspend;
			clock-latency-ns = <0x9c40>;
		};
	};

	iep@ff3a0000 {
		power-domains = <0x3b 0x05>;
		iommus = <0x41>;
		clock-names = "axi\0ahb";
		interrupts = <0x00 0x1f 0x04>;
		clocks = <0x02 0x9b 0x02 0x153>;
		compatible = "rockchip,rk3328-iep\0rockchip,rk3228-iep";
		interrupt-names = "iep";
		reg = <0x00 0xff3a0000 0x00 0x800>;
		phandle = <0x93>;
	};

	sdio-pwrseq {
		pinctrl-names = "default";
		pinctrl-0 = <0xf8>;
		reset-gpios = <0xa4 0x08 0x01>;
		compatible = "mmc-pwrseq-simple";
		post-power-on-delay-ms = <0xc8>;
		phandle = <0xf5>;
	};

	usb@ff5c0000 {
		phy-names = "usb";
		interrupts = <0x00 0x10 0x04>;
		clocks = <0x02 0x14e 0x4b>;
		compatible = "generic-ehci";
		status = "okay";
		phys = <0x5a>;
		reg = <0x00 0xff5c0000 0x00 0x10000>;
		phandle = <0x9d>;
	};

	aliases {
		i2c3 = "/i2c@ff180000";
		ethernet0 = "/ethernet@ff550000";
		gpio0 = "/pinctrl/gpio@ff210000";
		i2c1 = "/i2c@ff160000";
		mmc1 = "/mmc@ff520000";
		serial1 = "/serial@ff120000";
		gpio3 = "/pinctrl/gpio@ff240000";
		gpio1 = "/pinctrl/gpio@ff220000";
		i2c2 = "/i2c@ff170000";
		i2c0 = "/i2c@ff150000";
		mmc0 = "/mmc@ff500000";
		serial2 = "/serial@ff130000";
		serial0 = "/serial@ff110000";
		gpio2 = "/pinctrl/gpio@ff230000";
	};

	mmc@ff500000 {
		fifo-depth = <0x100>;
		pinctrl-names = "default";
		pinctrl-0 = <0x4c 0x4d 0x4e 0x4f>;
		clock-names = "biu\0ciu\0ciu-drive\0ciu-sample";
		cap-sd-highspeed;
		vqmmc-supply = <0x1c>;
		bus-width = <0x04>;
		resets = <0x02 0x6d>;
		interrupts = <0x00 0x0c 0x04>;
		clocks = <0x02 0x13d 0x02 0x21 0x02 0x4a 0x02 0x4e>;
		vmmc-supply = <0x1c>;
		compatible = "rockchip,rk3328-dw-mshc\0rockchip,rk3288-dw-mshc";
		status = "okay";
		disable-wp;
		reg = <0x00 0xff500000 0x00 0x4000>;
		phandle = <0x97>;
		max-frequency = <0x8f0d180>;
		cap-mmc-highspeed;
		reset-names = "reset";
	};

	iommu@ff3a0800 {
		power-domains = <0x3b 0x05>;
		clock-names = "aclk\0iface";
		interrupts = <0x00 0x1f 0x04>;
		clocks = <0x02 0x9b 0x02 0x153>;
		#iommu-cells = <0x00>;
		compatible = "rockchip,iommu";
		interrupt-names = "iep_mmu";
		reg = <0x00 0xff3a0800 0x00 0x40>;
		phandle = <0x41>;
	};

	mmc@ff5f0000 {
		fifo-depth = <0x100>;
		pinctrl-names = "default";
		pinctrl-0 = <0xd9 0xda 0xdc 0xde>;
		clock-names = "biu\0ciu\0ciu-drive\0ciu-sample";
		cap-sd-highspeed;
		bus-width = <0x04>;
		non-removable;
		resets = <0x02 0x68>;
		cap-sdio-irq;
		interrupts = <0x00 0x04 0x04>;
		clocks = <0x02 0x140 0x02 0x1f 0x02 0x4d 0x02 0x51>;
		keep-power-in-suspend;
		compatible = "rockchip,rk3328-dw-mshc\0rockchip,rk3288-dw-mshc";
		status = "okay";
		mmc-pwrseq = <0xf5>;
		reg = <0x00 0xff5f0000 0x00 0x4000>;
		phandle = <0x9f>;
		max-frequency = <0x8f0d180>;
		reset-names = "reset";
	};

	serial@ff110000 {
		reg-io-width = <0x04>;
		pinctrl-names = "default";
		pinctrl-0 = <0x1f 0x20 0x21>;
		clock-names = "baudclk\0apb_pclk";
		interrupts = <0x00 0x37 0x04>;
		clocks = <0x02 0x26 0x02 0xd2>;
		dma-names = "tx\0rx";
		compatible = "rockchip,rk3328-uart\0snps,dw-apb-uart";
		status = "disabled";
		reg = <0x00 0xff110000 0x00 0x100>;
		phandle = <0x77>;
		dmas = <0x10 0x02 0x10 0x03>;
		reg-shift = <0x02>;
	};

	adc@ff280000 {
		clock-names = "saradc\0apb_pclk";
		resets = <0x02 0x56>;
		interrupts = <0x00 0x50 0x04>;
		clocks = <0x02 0x25 0x02 0xea>;
		#io-channel-cells = <0x01>;
		compatible = "rockchip,rk3328-saradc\0rockchip,rk3399-saradc";
		status = "disabled";
		reg = <0x00 0xff280000 0x00 0x100>;
		phandle = <0x8d>;
		reset-names = "saradc-apb";
	};

	chosen {
		u-boot,version = "2022.07_armbian-2022.07-Se092-P621f-H28b4-V67df-Bbf55-R448a";
		linux,initrd-end = <0x00 0x7df22d1b>;
		bootargs = "root=UUID=b82a1580-8fe4-456f-abe4-a32ca973b55e rootwait rootfstype=ext4 splash=verbose console=ttyS2,1500000 console=tty1 consoleblank=0 loglevel=1 ubootpart=77c81bb8-01 usb-storage.quirks=0x2537:0x1066:u,0x2537:0x1068:u apparmor=1 security=apparmor systemd.unified_cgroup_hierarchy=0  cgroup_enable=cpuset cgroup_memory=1 cgroup_enable=memory swapaccount=1";
		linux,initrd-start = <0x00 0x7c359000>;
		stdout-path = "serial2:1500000n8";
	};

	i2s@ff020000 {
		clock-names = "i2s_clk\0i2s_hclk";
		interrupts = <0x00 0x1c 0x04>;
		clocks = <0x02 0x2b 0x02 0x139>;
		dma-names = "tx\0rx";
		#sound-dai-cells = <0x00>;
		compatible = "rockchip,rk3328-i2s\0rockchip,rk3066-i2s";
		status = "disabled";
		reg = <0x00 0xff020000 0x00 0x1000>;
		phandle = <0x73>;
		dmas = <0x10 0x00 0x10 0x01>;
	};

	hdmi@ff3c0000 {
		reg-io-width = <0x04>;
		pinctrl-names = "default";
		phy-names = "hdmi";
		pinctrl-0 = <0x43 0x44 0x45>;
		clock-names = "iahb\0isfr\0cec";
		interrupts = <0x00 0x23 0x04>;
		clocks = <0x02 0xe7 0x02 0x46 0x02 0x1e>;
		#sound-dai-cells = <0x00>;
		compatible = "rockchip,rk3328-dw-hdmi";
		status = "okay";
		rockchip,grf = <0x46>;
		phys = <0x42>;
		reg = <0x00 0xff3c0000 0x00 0x20000>;
		phandle = <0x0f>;

		ports {
			#address-cells = <0x01>;
			#size-cells = <0x00>;

			port@0 {
				reg = <0x00>;
				phandle = <0x94>;

				endpoint {
					remote-endpoint = <0x47>;
					phandle = <0x40>;
				};
			};

			port@1 {
				reg = <0x01>;
				phandle = <0x95>;
			};
		};
	};

	i2c@ff180000 {
		pinctrl-names = "default";
		#address-cells = <0x01>;
		pinctrl-0 = <0x2c>;
		clock-names = "i2c\0pclk";
		interrupts = <0x00 0x27 0x04>;
		clocks = <0x02 0x3a 0x02 0xd0>;
		#size-cells = <0x00>;
		compatible = "rockchip,rk3328-i2c\0rockchip,rk3399-i2c";
		status = "disabled";
		reg = <0x00 0xff180000 0x00 0x1000>;
		phandle = <0x7f>;
	};

	ir-receiver {
		compatible = "gpio-ir-receiver";
		gpios = <0x28 0x02 0x01>;
		linux,rc-map-name = "rc-beelink-gs1";
	};

	ethernet@ff550000 {
		phy-mode = "rmii";
		snps,txpbl = <0x04>;
		clock-names = "stmmaceth\0mac_clk_rx\0mac_clk_tx\0clk_mac_ref\0aclk_mac\0pclk_mac\0clk_macphy";
		local-mac-address = [46 4e 17 c7 65 4c];
		resets = <0x02 0x62>;
		interrupts = <0x00 0x15 0x04>;
		clocks = <0x02 0x54 0x02 0x53 0x02 0x53 0x02 0x55 0x02 0x95 0x02 0xde 0x02 0x56>;
		clock_in_out = "output";
		compatible = "rockchip,rk3328-gmac";
		status = "okay";
		rockchip,grf = <0x46>;
		tx-fifo-depth = <0x800>;
		interrupt-names = "macirq";
		rx-fifo-depth = <0x1000>;
		reg = <0x00 0xff550000 0x00 0x10000>;
		phandle = <0x9b>;
		phy-handle = <0x56>;
		reset-names = "stmmaceth";

		mdio {
			#address-cells = <0x01>;
			#size-cells = <0x00>;
			compatible = "snps,dwmac-mdio";

			ethernet-phy@0 {
				pinctrl-names = "default";
				pinctrl-0 = <0x57 0x58>;
				resets = <0x02 0x64>;
				clocks = <0x02 0x56>;
				compatible = "ethernet-phy-id1234.d400\0ethernet-phy-ieee802.3-c22";
				phy-is-integrated;
				reg = <0x00>;
				phandle = <0x56>;
			};
		};
	};

	video-codec@ff350000 {
		power-domains = <0x3b 0x08>;
		iommus = <0x3d>;
		clock-names = "aclk\0hclk";
		interrupts = <0x00 0x09 0x04>;
		clocks = <0x02 0x8f 0x02 0x146>;
		compatible = "rockchip,rk3328-vpu";
		interrupt-names = "vdpu";
		reg = <0x00 0xff350000 0x00 0x800>;
		phandle = <0x90>;
	};

	pdm@ff040000 {
		pinctrl-names = "default\0sleep";
		pinctrl-0 = <0x12 0x13 0x14 0x15 0x16>;
		clock-names = "pdm_clk\0pdm_hclk";
		clocks = <0x02 0x3d 0x02 0x152>;
		dma-names = "rx";
		compatible = "rockchip,pdm";
		pinctrl-1 = <0x17 0x18 0x19 0x1a 0x1b>;
		status = "disabled";
		reg = <0x00 0xff040000 0x00 0x1000>;
		phandle = <0x75>;
		dmas = <0x10 0x10>;
	};

	external-gmac-clock {
		clock-output-names = "gmac_clkin";
		#clock-cells = <0x00>;
		clock-frequency = <0x7735940>;
		compatible = "fixed-clock";
		phandle = <0x53>;
	};

	cpus {
		#address-cells = <0x02>;
		#size-cells = <0x00>;

		cpu@1 {
			d-cache-line-size = <0x40>;
			cpu-supply = <0x06>;
			clocks = <0x02 0x06>;
			i-cache-line-size = <0x40>;
			cpu-idle-states = <0x03>;
			device_type = "cpu";
			compatible = "arm,cortex-a53";
			dynamic-power-coefficient = <0x78>;
			d-cache-size = <0x8000>;
			next-level-cache = <0x05>;
			i-cache-size = <0x8000>;
			reg = <0x00 0x01>;
			enable-method = "psci";
			phandle = <0x0a>;
			d-cache-sets = <0x80>;
			operating-points-v2 = <0x04>;
			i-cache-sets = <0x100>;
			#cooling-cells = <0x02>;
		};

		l2-cache {
			cache-size = <0x40000>;
			cache-level = <0x02>;
			cache-sets = <0x100>;
			cache-unified;
			compatible = "cache";
			cache-line-size = <0x40>;
			phandle = <0x05>;
		};

		idle-states {
			entry-method = "psci";

			cpu-sleep {
				entry-latency-us = <0x78>;
				local-timer-stop;
				exit-latency-us = <0xfa>;
				arm,psci-suspend-param = <0x10000>;
				compatible = "arm,idle-state";
				phandle = <0x03>;
				min-residency-us = <0x384>;
			};
		};

		cpu@2 {
			d-cache-line-size = <0x40>;
			cpu-supply = <0x06>;
			clocks = <0x02 0x06>;
			i-cache-line-size = <0x40>;
			cpu-idle-states = <0x03>;
			device_type = "cpu";
			compatible = "arm,cortex-a53";
			dynamic-power-coefficient = <0x78>;
			d-cache-size = <0x8000>;
			next-level-cache = <0x05>;
			i-cache-size = <0x8000>;
			reg = <0x00 0x02>;
			enable-method = "psci";
			phandle = <0x0b>;
			d-cache-sets = <0x80>;
			operating-points-v2 = <0x04>;
			i-cache-sets = <0x100>;
			#cooling-cells = <0x02>;
		};

		cpu@0 {
			d-cache-line-size = <0x40>;
			cpu-supply = <0x06>;
			clocks = <0x02 0x06>;
			i-cache-line-size = <0x40>;
			cpu-idle-states = <0x03>;
			device_type = "cpu";
			compatible = "arm,cortex-a53";
			dynamic-power-coefficient = <0x78>;
			d-cache-size = <0x8000>;
			next-level-cache = <0x05>;
			i-cache-size = <0x8000>;
			reg = <0x00 0x00>;
			enable-method = "psci";
			phandle = <0x09>;
			d-cache-sets = <0x80>;
			operating-points-v2 = <0x04>;
			i-cache-sets = <0x100>;
			#cooling-cells = <0x02>;
		};

		cpu@3 {
			d-cache-line-size = <0x40>;
			cpu-supply = <0x06>;
			clocks = <0x02 0x06>;
			i-cache-line-size = <0x40>;
			cpu-idle-states = <0x03>;
			device_type = "cpu";
			compatible = "arm,cortex-a53";
			dynamic-power-coefficient = <0x78>;
			d-cache-size = <0x8000>;
			next-level-cache = <0x05>;
			i-cache-size = <0x8000>;
			reg = <0x00 0x03>;
			enable-method = "psci";
			phandle = <0x0c>;
			d-cache-sets = <0x80>;
			operating-points-v2 = <0x04>;
			i-cache-sets = <0x100>;
			#cooling-cells = <0x02>;
		};
	};

	spdif-out {
		#sound-dai-cells = <0x00>;
		compatible = "linux,spdif-dit";
		phandle = <0xf6>;
	};

	__symbols__ {
		i2c3 = "/i2c@ff180000";
		vdd_arm = "/i2c@ff160000/pmic@18/regulators/DCDC_REG2";
		i2s1_sdio1 = "/pinctrl/i2s1/i2s1-sdio1";
		pdmm0_sdi3 = "/pinctrl/pdm-0/pdmm0-sdi3";
		usb30_host_drv = "/pinctrl/usb3/usb30-host-drv";
		pcfg_pull_none_4ma = "/pinctrl/pcfg-pull-none-4ma";
		i2s2m1_mclk = "/pinctrl/i2s2-1/i2s2m1-mclk";
		i2s2m1_lrcktx = "/pinctrl/i2s2-1/i2s2m1-lrcktx";
		i2s2m0_lrckrx = "/pinctrl/i2s2-0/i2s2m0-lrckrx";
		pcfg_input_high = "/pinctrl/pcfg-input-high";
		spdif_sound = "/spdif-sound";
		pdmm0_sdi1_sleep = "/pinctrl/pdm-0/pdmm0-sdi1-sleep";
		spdif_out = "/spdif-out";
		hdmi_in_vop = "/hdmi@ff3c0000/ports/port@0/endpoint";
		sdmmc0ext_cmd = "/pinctrl/sdmmc0ext/sdmmc0ext-cmd";
		gpio0 = "/pinctrl/gpio@ff210000";
		saradc = "/adc@ff280000";
		bt_dis = "/pinctrl/wifi/bt-dis";
		emmc_rstnout = "/pinctrl/emmc/emmc-rstnout";
		sdmmc1_pins = "/pinctrl/sdmmc1/sdmmc1-pins";
		spi0m0_tx = "/pinctrl/spi0-0/spi0m0-tx";
		crypto = "/crypto@ff060000";
		pinctrl = "/pinctrl";
		rtl8211f = "/ethernet@ff540000/mdio/ethernet-phy@0";
		i2s2m1_lrckrx = "/pinctrl/i2s2-1/i2sm1-lrckrx";
		pdmm0_clk = "/pinctrl/pdm-0/pdmm0-clk";
		i2s1 = "/i2s@ff010000";
		pdm = "/pdm@ff040000";
		vcc_host_5v = "/regulator-usb3-current-switch";
		vdd_logic = "/i2c@ff160000/pmic@18/regulators/DCDC_REG1";
		uart2m1_xfer = "/pinctrl/uart2-1/uart2m1-xfer";
		hdmi_cec = "/pinctrl/hdmi_pin/hdmi-cec";
		i2c1 = "/i2c@ff160000";
		fephyled_linkm1 = "/pinctrl/gmac2phy/fephyled-linkm1";
		sdmmc1_bus1 = "/pinctrl/sdmmc1/sdmmc1-bus1";
		pdmm0_sdi1 = "/pinctrl/pdm-0/pdmm0-sdi1";
		u2phy_otg = "/syscon@ff450000/usb2phy@100/otg-port";
		pdmm0_fsync = "/pinctrl/pdm-0/pdmm0-fsync";
		sdmmc0ext_bus4 = "/pinctrl/sdmmc0ext/sdmmc0ext-bus4";
		sdmmc0_clk = "/pinctrl/sdmmc0/sdmmc0-clk";
		emmc_cmd = "/pinctrl/emmc/emmc-cmd";
		pcfg_pull_none = "/pinctrl/pcfg-pull-none";
		otp_out = "/pinctrl/tsadc/otp-out";
		pdmm0_clk_sleep = "/pinctrl/pdm-0/pdmm0-clk-sleep";
		dmac = "/dma-controller@ff1f0000";
		spi0m0_rx = "/pinctrl/spi0-0/spi0m0-rx";
		spi0m1_clk = "/pinctrl/spi0-1/spi0m1-clk";
		fephyled_duplex = "/pinctrl/gmac2phy/fephyled-duplex";
		target = "/thermal-zones/soc-thermal/trips/trip-point1";
		i2s1_mclk = "/pinctrl/i2s1/i2s1-mclk";
		vcc_sys = "/regulator-vcc-sys";
		i2s2m0_sleep = "/pinctrl/i2s2-0/i2s2m0-sleep";
		dvp_d2d9_m1 = "/pinctrl/cif-1/dvp-d2d9-m1";
		i2s2m0_sdo = "/pinctrl/i2s2-0/i2s2m0-sdo";
		gpu = "/gpu@ff300000";
		spi0 = "/spi@ff190000";
		iep = "/iep@ff3a0000";
		pwm0_pin = "/pinctrl/pwm0/pwm0-pin";
		hdmi_hpd = "/pinctrl/hdmi_pin/hdmi-hpd";
		usb_host0_ohci = "/usb@ff5d0000";
		sdmmc0_dectn = "/pinctrl/sdmmc0/sdmmc0-dectn";
		i2s2m0_mclk = "/pinctrl/i2s2-0/i2s2m0-mclk";
		sdmmc1_cmd = "/pinctrl/sdmmc1/sdmmc1-cmd";
		logic_leakage = "/efuse@ff260000/logic-leakage@19";
		usbdrd3 = "/usb@ff600000";
		tsadc_pin = "/pinctrl/tsadc_pin/tsadc-pin";
		sdmmc0_pins = "/pinctrl/sdmmc0/sdmmc0-pins";
		pcfg_input = "/pinctrl/pcfg-input";
		spi0m0_cs0 = "/pinctrl/spi0-0/spi0m0-cs0";
		sdmmc0m1_pwren = "/pinctrl/sdmmc0-1/sdmmc0m1-pwren";
		uart2m0_xfer = "/pinctrl/uart2-0/uart2m0-xfer";
		sdmmc0ext_clk = "/pinctrl/sdmmc0ext/sdmmc0ext-clk";
		sdmmc0_bus1 = "/pinctrl/sdmmc0/sdmmc0-bus1";
		cpu0_opp_table = "/opp-table-0";
		i2c3_xfer = "/pinctrl/i2c3/i2c3-xfer";
		power = "/syscon@ff100000/power-controller";
		i2c3_pins = "/pinctrl/i2c3/i2c3-pins";
		pwm3 = "/pwm@ff1b0030";
		gmac_clkin = "/external-gmac-clock";
		vdec_mmu = "/iommu@ff360480";
		chip_en = "/pinctrl/wifi/chip-en";
		emmc_clk = "/pinctrl/emmc/emmc-clk";
		cru = "/clock-controller@ff440000";
		spdifm1_tx = "/pinctrl/spdif-1/spdifm1-tx";
		cpu3 = "/cpus/cpu@3";
		pdmm0_sdi2_sleep = "/pinctrl/pdm-0/pdmm0-sdi2-sleep";
		uart2 = "/serial@ff130000";
		host_wake_bt = "/pinctrl/wifi/host-wake-bt";
		pcfg_pull_up_12ma = "/pinctrl/pcfg-pull-up-12ma";
		u2phy = "/syscon@ff450000/usb2phy@100";
		pcfg_output_low = "/pinctrl/pcfg-output-low";
		sdio_pwrseq = "/sdio-pwrseq";
		vdec = "/video-codec@ff360000";
		gic = "/interrupt-controller@ff811000";
		sdmmc1_clk = "/pinctrl/sdmmc1/sdmmc1-clk";
		sdmmc1_pwren = "/pinctrl/sdmmc1/sdmmc1-pwren";
		uart0_rts_pin = "/pinctrl/uart0/uart0-rts-pin";
		pwm1 = "/pwm@ff1b0010";
		threshold = "/thermal-zones/soc-thermal/trips/trip-point0";
		vpu = "/video-codec@ff350000";
		spi0m2_tx = "/pinctrl/spi0-2/spi0m2-tx";
		spi0m2_clk = "/pinctrl/spi0-2/spi0m2-clk";
		emmc_bus1 = "/pinctrl/emmc/emmc-bus1";
		otp_pin = "/pinctrl/tsadc/otp-pin";
		vop_out_hdmi = "/vop@ff370000/port/endpoint";
		xin24m = "/xin24m";
		i2s2m1_sdo = "/pinctrl/i2s2-1/i2s2m1-sdo";
		pcfg_pull_up_2ma = "/pinctrl/pcfg-pull-up-2ma";
		tsadc = "/tsadc@ff250000";
		uart0_cts = "/pinctrl/uart0/uart0-cts";
		gpio3 = "/pinctrl/gpio@ff240000";
		sdmmc0_wrprt = "/pinctrl/sdmmc0/sdmmc0-wrprt";
		pwm1_pin = "/pinctrl/pwm1/pwm1-pin";
		gpu_opp_table = "/opp-table-gpu";
		pcfg_output_high = "/pinctrl/pcfg-output-high";
		cpu1 = "/cpus/cpu@1";
		i2s2m1_sleep = "/pinctrl/i2s2-1/i2s2m1-sleep";
		uart0 = "/serial@ff110000";
		i2c2_xfer = "/pinctrl/i2c2/i2c2-xfer";
		pmic_int_l = "/pinctrl/pmic/pmic-int-l";
		i2s2m0_sdi = "/pinctrl/i2s2-0/i2s2m0-sdi";
		fephyled_speed10 = "/pinctrl/gmac2phy/fephyled-speed10";
		sdmmc1_dectn = "/pinctrl/sdmmc1/sdmmc1-dectn";
		spi0m2_rx = "/pinctrl/spi0-2/spi0m2-rx";
		sdmmc1_bus4 = "/pinctrl/sdmmc1/sdmmc1-bus4";
		i2s1_sdio2 = "/pinctrl/i2s1/i2s1-sdio2";
		emmc = "/mmc@ff520000";
		efuse_id = "/efuse@ff260000/id@7";
		vop_mmu = "/iommu@ff373f00";
		iep_mmu = "/iommu@ff3a0800";
		usb2phy_grf = "/syscon@ff450000";
		spdif = "/spdif@ff030000";
		spi0m1_cs0 = "/pinctrl/spi0-1/spi0m1-cs0";
		wifi_enable_h = "/pinctrl/wifi/wifi_enable_h";
		fephyled_rxm1 = "/pinctrl/gmac2phy/fephyled-rxm1";
		vdd_11 = "/i2c@ff160000/pmic@18/regulators/LDO_REG3";
		cpu_leakage = "/efuse@ff260000/cpu-leakage@17";
		i2s1_sdo = "/pinctrl/i2s1/i2s1-sdo";
		gpio1 = "/pinctrl/gpio@ff220000";
		tsadc_int = "/pinctrl/tsadc_pin/tsadc-int";
		wdt = "/watchdog@ff1a0000";
		hdmi_out = "/hdmi@ff3c0000/ports/port@1";
		i2s2 = "/i2s@ff020000";
		grf_gpio = "/syscon@ff100000/gpio";
		hdmii2c_xfer = "/pinctrl/hdmi_i2c/hdmii2c-xfer";
		i2c2 = "/i2c@ff170000";
		pdmm0_sdi2 = "/pinctrl/pdm-0/pdmm0-sdi2";
		emmc_bus8 = "/pinctrl/emmc/emmc-bus8";
		usb_host0_ehci = "/usb@ff5c0000";
		vcc18_emmc = "/i2c@ff160000/pmic@18/regulators/LDO_REG2";
		vcc_io = "/i2c@ff160000/pmic@18/regulators/DCDC_REG4";
		pcfg_pull_up_8ma = "/pinctrl/pcfg-pull-up-8ma";
		i2c1_xfer = "/pinctrl/i2c1/i2c1-xfer";
		pcfg_pull_down_4ma = "/pinctrl/pcfg-pull-down-4ma";
		vcc_ddr = "/i2c@ff160000/pmic@18/regulators/DCDC_REG3";
		pwmir_pin = "/pinctrl/pwmir/pwmir-pin";
		u2phy_host = "/syscon@ff450000/usb2phy@100/host-port";
		usb20_otg = "/usb@ff580000";
		pdmm0_sdi3_sleep = "/pinctrl/pdm-0/pdmm0-sdi3-sleep";
		pdmm0_fsync_sleep = "/pinctrl/pdm-0/pdmm0-fsync-sleep";
		sdmmc0_bus4 = "/pinctrl/sdmmc0/sdmmc0-bus4";
		pcfg_pull_none_2ma = "/pinctrl/pcfg-pull-none-2ma";
		emmc_pwren = "/pinctrl/emmc/emmc-pwren";
		vop_out = "/vop@ff370000/port";
		sdmmc = "/mmc@ff500000";
		i2s0 = "/i2s@ff000000";
		i2c0 = "/i2c@ff150000";
		soc_thermal = "/thermal-zones/soc-thermal";
		pdmm0_sdi0 = "/pinctrl/pdm-0/pdmm0-sdi0";
		spdifm0_tx = "/pinctrl/spdif-0/spdifm0-tx";
		uart0_rts = "/pinctrl/uart0/uart0-rts";
		vdd_18 = "/i2c@ff160000/pmic@18/regulators/LDO_REG1";
		pcfg_pull_none_12ma = "/pinctrl/pcfg-pull-none-12ma";
		io_domains = "/syscon@ff100000/io-domains";
		h265e_mmu = "/iommu@ff330200";
		sdmmc0ext_dectn = "/pinctrl/sdmmc0ext/sdmmc0ext-dectn";
		uart1_cts = "/pinctrl/uart1/uart1-cts";
		gmac2io = "/ethernet@ff540000";
		pwm2_pin = "/pinctrl/pwm2/pwm2-pin";
		bt_wake_host = "/pinctrl/wifi/bt-wake-host";
		sdmmc0m0_pin = "/pinctrl/sdmmc0-0/sdmmc0m0-pin";
		spi0m0_cs1 = "/pinctrl/spi0-0/spi0m0-cs1";
		sdio = "/mmc@ff510000";
		sdmmc1_wrprt = "/pinctrl/sdmmc1/sdmmc1-wrprt";
		codec = "/codec@ff410000";
		i2s2m1_sdi = "/pinctrl/i2s2-1/i2s2m1-sdi";
		dvp_d2d9_m0 = "/pinctrl/cif-0/dvp-d2d9-m0";
		i2s2m1_sclk = "/pinctrl/i2s2-1/i2s2m1-sclk";
		vepu_mmu = "/iommu@ff340800";
		efuse_cpu_version = "/efuse@ff260000/cpu-version@1a";
		hdmiphy = "/phy@ff430000";
		sdmmc0ext_pins = "/pinctrl/sdmmc0ext/sdmmc0ext-pins";
		vop = "/vop@ff370000";
		spi0m1_tx = "/pinctrl/spi0-1/spi0m1-tx";
		i2c0_xfer = "/pinctrl/i2c0/i2c0-xfer";
		emmc_bus4 = "/pinctrl/emmc/emmc-bus4";
		spi0m2_cs0 = "/pinctrl/spi0-2/spi0m2-cs0";
		sdmmc0ext_bus1 = "/pinctrl/sdmmc0ext/sdmmc0ext-bus1";
		soc_crit = "/thermal-zones/soc-thermal/trips/soc-crit";
		pdmm0_sdi0_sleep = "/pinctrl/pdm-0/pdmm0-sdi0-sleep";
		pcfg_pull_down = "/pinctrl/pcfg-pull-down";
		wl_wake_host = "/pinctrl/wifi/wl-wake-host";
		pcfg_pull_up = "/pinctrl/pcfg-pull-up";
		vpu_mmu = "/iommu@ff350800";
		spi0m1_rx = "/pinctrl/spi0-1/spi0m1-rx";
		uart1_xfer = "/pinctrl/uart1/uart1-xfer";
		pcfg_pull_none_8ma = "/pinctrl/pcfg-pull-none-8ma";
		i2s1_sdi = "/pinctrl/i2s1/i2s1-sdi";
		pcfg_pull_up_4ma = "/pinctrl/pcfg-pull-up-4ma";
		phy = "/ethernet@ff550000/mdio/ethernet-phy@0";
		fephyled_txm1 = "/pinctrl/gmac2phy/fephyled-txm1";
		gmac2phy = "/ethernet@ff550000";
		i2s1_lrcktx = "/pinctrl/i2s1/i2s1-lrcktx";
		i2s1_sclk = "/pinctrl/i2s1/i2s1-sclk";
		pwm2 = "/pwm@ff1b0020";
		CPU_SLEEP = "/cpus/idle-states/cpu-sleep";
		display_subsystem = "/display-subsystem";
		i2s2m0_sclk = "/pinctrl/i2s2-0/i2s2m0-sclk";
		efuse = "/efuse@ff260000";
		i2s1_sleep = "/pinctrl/i2s1/i2s1-sleep";
		wl_dis = "/pinctrl/wifi/wl-dis";
		cpu2 = "/cpus/cpu@2";
		spi0m0_clk = "/pinctrl/spi0-0/spi0m0-clk";
		uart1 = "/serial@ff120000";
		hdmi = "/hdmi@ff3c0000";
		i2s1_lrckrx = "/pinctrl/i2s1/i2s1-lrckrx";
		rgmiim1_pins = "/pinctrl/gmac-1/rgmiim1-pins";
		hdmi_in = "/hdmi@ff3c0000/ports/port@0";
		analog_sound = "/analog-sound";
		l2_cache = "/cpus/l2-cache";
		i2s1_sdio3 = "/pinctrl/i2s1/i2s1-sdio3";
		uart1_rts = "/pinctrl/uart1/uart1-rts";
		grf = "/syscon@ff100000";
		sdmmc0_cmd = "/pinctrl/sdmmc0/sdmmc0-cmd";
		sdmmc0ext_wrprt = "/pinctrl/sdmmc0ext/sdmmc0ext-wrprt";
		rmiim1_pins = "/pinctrl/gmac-1/rmiim1-pins";
		pwm0 = "/pwm@ff1b0000";
		hdmi_sound = "/hdmi-sound";
		sdmmc0m1_pin = "/pinctrl/sdmmc0-1/sdmmc0m1-pin";
		spi0m1_cs1 = "/pinctrl/spi0-1/spi0m1-cs1";
		uart0_xfer = "/pinctrl/uart0/uart0-xfer";
		uart1_rts_pin = "/pinctrl/uart1/uart1-rts-pin";
		gpio2 = "/pinctrl/gpio@ff230000";
		sdmmc0m0_pwren = "/pinctrl/sdmmc0-0/sdmmc0m0-pwren";
		cpu0 = "/cpus/cpu@0";
		spdifm2_tx = "/pinctrl/spdif-2/spdifm2-tx";
		i2s2m0_lrcktx = "/pinctrl/i2s2-0/i2s2m0-lrcktx";
		sdmmc_ext = "/mmc@ff5f0000";
	};

	clock-controller@ff440000 {
		#reset-cells = <0x01>;
		clock-names = "xin24m";
		assigned-clocks = <0x02 0x78 0x02 0x3d 0x02 0x1e 0x02 0x26 0x02 0x27 0x02 0x28 0x02 0x88 0x02 0x89 0x02 0x8e 0x02 0x85 0x02 0x83 0x02 0x8a 0x02 0x8c 0x02 0x8d 0x02 0x41 0x02 0x42 0x02 0x44 0x02 0x43 0x02 0x22 0x02 0x5c 0x02 0x35 0x02 0x06 0x02 0x04 0x02 0x03 0x02 0x88 0x02 0x148 0x02 0xd8 0x02 0x89 0x02 0x134 0x02 0xe6 0x02 0x1e>;
		assigned-clock-parents = <0x02 0x7a 0x02 0x01 0x02 0x04 0x49 0x49 0x49>;
		assigned-clock-rates = <0x00 0x3a98000 0x00 0x16e3600 0x16e3600 0x16e3600 0xe4e1c0 0xe4e1c0 0x11e1a300 0x5f5e100 0x1dcd6500 0x5f5e100 0x2faf080 0x5f5e100 0x5f5e100 0x5f5e100 0x2faf080 0x2faf080 0x2faf080 0x2faf080 0x16e3600 0x23c34600 0x1d4c0000 0x47868c00 0x8f0d180 0x47868c0 0x47868c0 0x8f0d180 0x47868c0 0x47868c0 0x8000>;
		clocks = <0x49>;
		#clock-cells = <0x01>;
		compatible = "rockchip,rk3328-cru";
		rockchip,grf = <0x46>;
		reg = <0x00 0xff440000 0x00 0x1000>;
		phandle = <0x02>;
	};

	spi@ff190000 {
		pinctrl-names = "default";
		#address-cells = <0x01>;
		pinctrl-0 = <0x2d 0x2e 0x2f 0x30>;
		clock-names = "spiclk\0apb_pclk";
		interrupts = <0x00 0x31 0x04>;
		clocks = <0x02 0x20 0x02 0xd1>;
		#size-cells = <0x00>;
		dma-names = "tx\0rx";
		compatible = "rockchip,rk3328-spi\0rockchip,rk3066-spi";
		status = "disabled";
		reg = <0x00 0xff190000 0x00 0x1000>;
		phandle = <0x80>;
		dmas = <0x10 0x08 0x10 0x09>;
	};

	pwm@ff1b0030 {
		pinctrl-names = "default";
		pinctrl-0 = <0x34>;
		clock-names = "pwm\0pclk";
		clocks = <0x02 0x3c 0x02 0xd6>;
		#pwm-cells = <0x03>;
		compatible = "rockchip,rk3328-pwm";
		status = "disabled";
		reg = <0x00 0xff1b0030 0x00 0x10>;
		phandle = <0x85>;
	};

	usb@ff5d0000 {
		phy-names = "usb";
		interrupts = <0x00 0x11 0x04>;
		clocks = <0x02 0x14e 0x4b>;
		compatible = "generic-ohci";
		status = "disabled";
		phys = <0x5a>;
		reg = <0x00 0xff5d0000 0x00 0x10000>;
		phandle = <0x9e>;
	};

	watchdog@ff1a0000 {
		interrupts = <0x00 0x28 0x04>;
		clocks = <0x02 0xec>;
		compatible = "rockchip,rk3328-wdt\0snps,dw-wdt";
		reg = <0x00 0xff1a0000 0x00 0x100>;
		phandle = <0x81>;
	};

	codec@ff410000 {
		clock-names = "pclk\0mclk";
		clocks = <0x02 0xeb 0x02 0x2a>;
		mute-gpios = <0x48 0x00 0x01>;
		#sound-dai-cells = <0x00>;
		compatible = "rockchip,rk3328-codec";
		status = "okay";
		rockchip,grf = <0x46>;
		reg = <0x00 0xff410000 0x00 0x1000>;
		phandle = <0x08>;
	};

	pwm@ff1b0020 {
		pinctrl-names = "default";
		pinctrl-0 = <0x33>;
		clock-names = "pwm\0pclk";
		clocks = <0x02 0x3c 0x02 0xd6>;
		#pwm-cells = <0x03>;
		compatible = "rockchip,rk3328-pwm";
		status = "disabled";
		reg = <0x00 0xff1b0020 0x00 0x10>;
		phandle = <0x84>;
	};

	mmc@ff510000 {
		fifo-depth = <0x100>;
		clock-names = "biu\0ciu\0ciu-drive\0ciu-sample";
		resets = <0x02 0x6e>;
		interrupts = <0x00 0x0d 0x04>;
		clocks = <0x02 0x13e 0x02 0x22 0x02 0x4b 0x02 0x4f>;
		compatible = "rockchip,rk3328-dw-mshc\0rockchip,rk3288-dw-mshc";
		status = "disabled";
		reg = <0x00 0xff510000 0x00 0x4000>;
		phandle = <0x98>;
		max-frequency = <0x8f0d180>;
		reset-names = "reset";
	};

	pwm@ff1b0010 {
		pinctrl-names = "default";
		pinctrl-0 = <0x32>;
		clock-names = "pwm\0pclk";
		clocks = <0x02 0x3c 0x02 0xd6>;
		#pwm-cells = <0x03>;
		compatible = "rockchip,rk3328-pwm";
		status = "disabled";
		reg = <0x00 0xff1b0010 0x00 0x10>;
		phandle = <0x83>;
	};

	interrupt-controller@ff811000 {
		#address-cells = <0x00>;
		interrupts = <0x01 0x09 0xf04>;
		compatible = "arm,gic-400";
		#interrupt-cells = <0x03>;
		reg = <0x00 0xff811000 0x00 0x1000 0x00 0xff812000 0x00 0x2000 0x00 0xff814000 0x00 0x2000 0x00 0xff816000 0x00 0x2000>;
		phandle = <0x01>;
		interrupt-controller;
	};

	memory {
		device_type = "memory";
		reg = <0x00 0x200000 0x00 0x7fe00000>;
	};

	serial@ff120000 {
		reg-io-width = <0x04>;
		clock-names = "baudclk\0apb_pclk";
		interrupts = <0x00 0x38 0x04>;
		clocks = <0x02 0x27 0x02 0xd3>;
		dma-names = "tx\0rx";
		compatible = "rockchip,rk3328-uart\0snps,dw-apb-uart";
		status = "okay";
		reg = <0x00 0xff120000 0x00 0x100>;
		phandle = <0x78>;
		dmas = <0x10 0x04 0x10 0x05>;
		reg-shift = <0x02>;
	};

	pwm@ff1b0000 {
		pinctrl-names = "default";
		pinctrl-0 = <0x31>;
		clock-names = "pwm\0pclk";
		clocks = <0x02 0x3c 0x02 0xd6>;
		#pwm-cells = <0x03>;
		compatible = "rockchip,rk3328-pwm";
		status = "disabled";
		reg = <0x00 0xff1b0000 0x00 0x10>;
		phandle = <0x82>;
	};
};
